AUTOSAR XML (schema 4-2-2)
package /Components
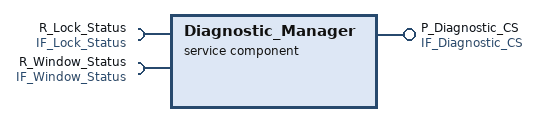
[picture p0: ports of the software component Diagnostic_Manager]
  service sw component type Diagnostic_Manager
    provide port P_Diagnostic_CS: provided-interface=IF_Diagnostic_CS
    require port R_Lock_Status: required-interface=IF_Lock_Status
    require port R_Window_Status: required-interface=IF_Window_Status
    behavior Diagnostic_Manager_InternalBehavior
      init event Diag_Init_Event: start-on-event=Diag_Init
      operation invoked event Diag_Read_DID_Invoked: start-on-event=Diag_Read_DID
      operation invoked event Diag_Clear_DTC_Invoked: start-on-event=Diag_Clear_DTC
      operation invoked event Diag_Routine_Control_Invoked: start-on-event=Diag_Routine_Control
      4 x runnable:
        Diag_Init
        Diag_Read_DID
          data-receive-point-by-arguments:
            access VA_Read_LockStatus: accessed-variable=R_Lock_Status.lock_status
            access VA_Read_WindowStatus: accessed-variable=R_Window_Status.window_status
        Diag_Clear_DTC
          data-receive-point-by-arguments:
            access VA_Read_LockStatus_ForClear: accessed-variable=R_Lock_Status.lock_status
        Diag_Routine_Control
          data-receive-point-by-arguments:
            access VA_Read_WindowStatus_ForRoutine: accessed-variable=R_Window_Status.window_status
